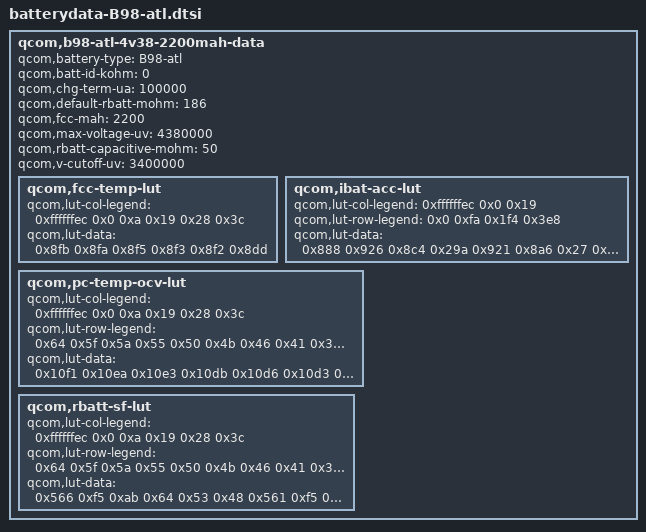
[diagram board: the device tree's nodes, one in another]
/* Copyright (c) 2020, The Linux Foundation. All rights reserved.
*  Copyright (c) 2020, the_shahnawaz_sheikh (sheikhshahnawaz41299).
*
* This program is free software; you can redistribute it and/or modify
* it under the terms of the GNU General Public License version 2 and
* only version 2 as published by the Free Software Foundation.
*
* This program is distributed in the hope that it will be useful,
* but WITHOUT ANY WARRANTY; without even the implied warranty of
* MERCHANTABILITY or FITNESS FOR A PARTICULAR PURPOSE.  See the
* GNU General Public License for more details.
*/

qcom,b98-atl-4v38-2200mah-data {
			qcom,battery-type = "B98-atl";
			qcom,batt-id-kohm = <0>;
			qcom,chg-term-ua = <100000>;
			qcom,default-rbatt-mohm = <186>;
			qcom,fcc-mah = <2200>;
			qcom,max-voltage-uv = <4380000>;
			qcom,rbatt-capacitive-mohm = <50>;
			qcom,v-cutoff-uv = <3400000>;

			qcom,fcc-temp-lut {
				qcom,lut-col-legend = <0xffffffec 0x0 0xa 0x19 0x28 0x3c>;
				qcom,lut-data = <0x8fb 0x8fa 0x8f5 0x8f3 0x8f2 0x8dd>;
			};

			qcom,ibat-acc-lut {
				qcom,lut-col-legend = <0xffffffec 0x0 0x19>;
				qcom,lut-row-legend = <0x0 0xfa 0x1f4 0x3e8>;
				qcom,lut-data = <0x888 0x926 0x8c4 0x29a 0x921 0x8a6 0x27 0x90f 0x892 0x6 0x8c9 0x866>;
			};

			qcom,pc-temp-ocv-lut {
				qcom,lut-col-legend = <0xffffffec 0x0 0xa 0x19 0x28 0x3c>;
				qcom,lut-row-legend = <0x64 0x5f 0x5a 0x55 0x50 0x4b 0x46 0x41 0x3c 0x37 0x32 0x2d 0x28 0x23 0x1e 0x19 0x14 0x10 0xd 0xb 0xa 0x9 0x8 0x7 0x6 0x5 0x4 0x3 0x2 0x1 0x0>;
				qcom,lut-data = <0x10f1 0x10ea 0x10e3 0x10db 0x10d6 0x10d3 0x109c 0x10b8 0x10ba 0x10bb 0x10ba 0x10b3 0x104d 0x107b 0x107c 0x1080 0x1080 0x107a 0x1004 0x1040 0x1042 0x1046 0x1047 0x1042 0xfc1 0x1009 0x100b 0x1010 0x1010 0x100c 0xf80 0xfd3 0xfd6 0xfdc 0xfdd 0xfda 0xf4e 0xf9b 0xfa2 0xfad 0xfae 0xfac 0xf23 0xf66 0xf6c 0xf81 0xf83 0xf82 0xf02 0xf3c 0xf3d 0xf53 0xf57 0xf57 0xee9 0xf1b 0xf19 0xf22 0xf26 0xf26 0xed3 0xeff 0xefc 0xf02 0xf05 0xf05 0xebe 0xee7 0xee5 0xeeb 0xeed 0xeee 0xea9 0xed3 0xed1 0xed8 0xeda 0xeda 0xe94 0xec3 0xec1 0xec8 0xec9 0xeca 0xe7c 0xeb6 0xeb5 0xebb 0xeba 0xeb5 0xe60 0xea8 0xea4 0xeac 0xea8 0xe9c 0xe3b 0xe8f 0xe89 0xe95 0xe93 0xe86 0xe14 0xe72 0xe70 0xe78 0xe76 0xe6b 0xdf2 0xe67 0xe66 0xe66 0xe61 0xe56 0xdd6 0xe62 0xe61 0xe63 0xe5e 0xe54 0xdc7 0xe5f 0xe5d 0xe61 0xe5d 0xe52 0xdb4 0xe5c 0xe59 0xe5f 0xe5c 0xe51 0xd9e 0xe57 0xe53 0xe5d 0xe5a 0xe4f 0xd87 0xe50 0xe4a 0xe59 0xe56 0xe4b 0xd6a 0xe42 0xe36 0xe4f 0xe4d 0xe3e 0xd49 0xe23 0xe16 0xe34 0xe2f 0xe1b 0xd20 0xdf6 0xdf0 0xe05 0xdff 0xdea 0xcf3 0xdc4 0xdbe 0xdc9 0xdbf 0xdac 0xcc2 0xd75 0xd6a 0xd77 0xd69 0xd5a 0xc8c 0xcdd 0xce4 0xce5 0xcf0 0xcc5 0xc4d 0xbb8 0xbb8 0xbb8 0xbe5 0xbb8>;
			};

			qcom,rbatt-sf-lut {
				qcom,lut-col-legend = <0xffffffec 0x0 0xa 0x19 0x28 0x3c>;
				qcom,lut-row-legend = <0x64 0x5f 0x5a 0x55 0x50 0x4b 0x46 0x41 0x3c 0x37 0x32 0x2d 0x28 0x23 0x1e 0x19 0x14 0x10 0xd 0xb 0xa 0x9 0x8 0x7 0x6 0x5 0x4 0x3 0x2 0x1 0x0>;
				qcom,lut-data = <0x566 0xf5 0xab 0x64 0x53 0x48 0x561 0xf5 0xab 0x64 0x53 0x49 0x4e6 0xed 0xac 0x66 0x54 0x49 0x498 0xf1 0xb0 0x68 0x56 0x4b 0x46c 0xf1 0xb6 0x6b 0x58 0x4d 0x44e 0xec 0xbd 0x70 0x5b 0x4f 0x447 0xdb 0xbe 0x75 0x5e 0x51 0x44e 0xc3 0xb3 0x7c 0x64 0x54 0x466 0xb0 0xa9 0x79 0x65 0x55 0x490 0x9c 0xa6 0x68 0x59 0x4e 0x4e8 0x93 0xa8 0x65 0x54 0x4b 0x584 0x94 0xaa 0x66 0x56 0x4c 0x64b 0x96 0xae 0x69 0x58 0x4e 0x749 0x9b 0xb5 0x6c 0x5a 0x51 0x89b 0xa1 0xc0 0x6e 0x59 0x4f 0xa7d 0xa7 0xca 0x6e 0x57 0x4b 0xd6e 0xaa 0xd1 0x6d 0x57 0x4b 0x1161 0xa6 0xd3 0x6d 0x57 0x4b 0x1473 0xa5 0xde 0x6a 0x54 0x4a 0x19a0 0xae 0xf2 0x6c 0x56 0x4c 0x1d03 0xb5 0x101 0x6e 0x58 0x4c 0x21b8 0xc0 0x117 0x71 0x5a 0x4e 0x278a 0xcc 0x131 0x74 0x5b 0x4e 0x3002 0xdf 0x158 0x79 0x5c 0x4f 0x3bdf 0xf7 0x184 0x7d 0x5d 0x4d 0x4ea6 0x109 0x1c8 0x80 0x5b 0x4d 0x6d54 0x13a 0x24d 0x83 0x5d 0x4f 0xa541 0x178 0x33c 0x8c 0x61 0x51 0x110be 0x2ef 0x619 0x9b 0x67 0x57 0x1d89f 0x5de 0xc04 0xf7 0x79 0x9f 0x3066f 0xbbd 0x957 0x1ef 0xf3 0x13d>;
			};
		};

